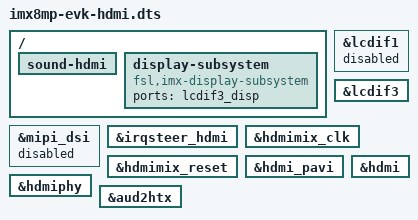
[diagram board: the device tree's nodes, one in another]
// SPDX-License-Identifier: (GPL-2.0+ OR MIT)
/*
 * Copyright 2020 NXP
 */

/dts-v1/;

#include "imx8mp-evk.dts"

/ {
	sound-hdmi {
		status = "okay";
	};

	display-subsystem {
		compatible = "fsl,imx-display-subsystem";
		ports = <&lcdif3_disp>;
	};
};

&mipi_dsi {
	status = "disabled";
};

&lcdif1 {
	status = "disabled";
};

&lcdif3 {
	status = "okay";
};

&irqsteer_hdmi {
	status = "okay";
};

&hdmimix_clk {
	status = "okay";
};

&hdmimix_reset {
	status = "okay";
};

&hdmi_pavi {
	status = "okay";
};

&hdmi {
	status = "okay";
};

&hdmiphy {
	status = "okay";
};

&aud2htx {
	status = "okay";
};
